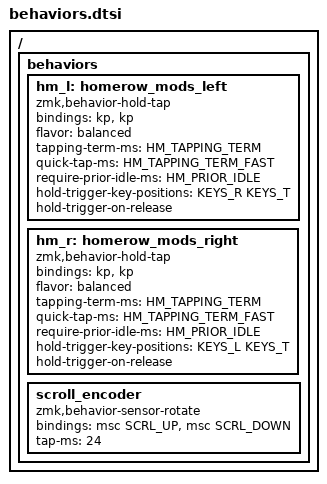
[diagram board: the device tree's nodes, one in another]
#include "zmk-helpers/key-labels/34.h"                                      // key-position labels

// KEYS_L / KEYS_R come from 34.h (identical to the old local definitions).
// 34.h's thumb labels (LH1 LH0 RH0 RH1 = 30 31 32 33) assume a 34-key board; this
// 35-key layout has left thumbs at 30-32 and right thumbs at 33-34, so list them explicitly.
#define KEYS_T 30 31 32 33 34                                               // thumb keys

#define HM_TAPPING_TERM 160       // max hold time (ms) before key becomes a modifier
#define HM_TAPPING_TERM_FAST 140  // shorter tapping term for index/pinky (faster fingers)
#define HM_PRIOR_IDLE 120         // must be idle this long before a hold-tap can become a mod (prevents misfires during fast typing)

/ {
    behaviors {
        hm_l: homerow_mods_left {
            compatible = "zmk,behavior-hold-tap";
            #binding-cells = <2>;
            bindings = <&kp>, <&kp>;

            flavor = "balanced";
            tapping-term-ms = <HM_TAPPING_TERM>;
            quick-tap-ms = <HM_TAPPING_TERM_FAST>;
            require-prior-idle-ms = <HM_PRIOR_IDLE>;
            hold-trigger-key-positions = <KEYS_R KEYS_T>;
            hold-trigger-on-release;
        };

        hm_r: homerow_mods_right {
            compatible = "zmk,behavior-hold-tap";
            #binding-cells = <2>;
            bindings = <&kp>, <&kp>;

            flavor = "balanced";
            tapping-term-ms = <HM_TAPPING_TERM>;
            quick-tap-ms = <HM_TAPPING_TERM_FAST>;
            require-prior-idle-ms = <HM_PRIOR_IDLE>;
            hold-trigger-key-positions = <KEYS_L KEYS_T>;
            hold-trigger-on-release;
        };

        scroll_encoder: scroll_encoder {
            compatible = "zmk,behavior-sensor-rotate";
            #sensor-binding-cells = <0>;
            bindings = <&msc SCRL_UP>, <&msc SCRL_DOWN>;
            tap-ms = <24>; // must outlast one &msc tick (16ms) with margin, or the release cancels it before any scroll is emitted
        };
    };
};
